# dm646x_cslr_edma3tc register map
Vendor: Texas Instruments
Peripheral module from a debugger description file.
Registers are 32-bit, access not given, reset 0x0 unless marked. A register's access mark holds for its fields unless they carry their own. Offsets are as the file gives them; lines under a group give offsets from that group; [hi:lo] are bit positions; {n}, {i} and the like mark numbered series; 'fields as' and 'values as' point back to an identical list; <NAME> marks a mode.

## EDMA3TC — Enhanced DMA Transfer controller.
0x00 PID ro — Peripheral Revision
{0x0+0x40*i} DFIREG[{i}] (i=0..3) group — Destination FIFO Registers
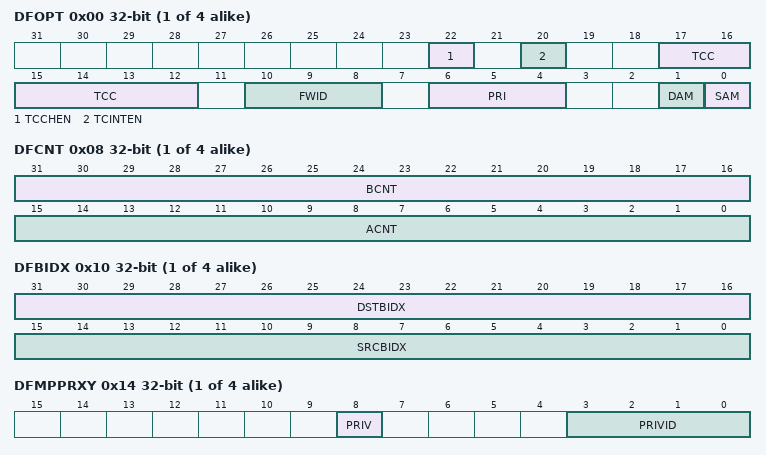
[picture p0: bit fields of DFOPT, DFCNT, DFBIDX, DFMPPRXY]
  0x00 DFOPT — Dst FIFO Set Option
    [22] TCCHEN rw — Transfer Complete chaining enable
      0=DISABLE (Transfer complete chaning disable); 1=ENABLE (Transfer complete chaning enable)
    [20] TCINTEN rw — Transfer Complete interrupt enable
      0=DISABLE (Transfer complete interrupt disable); 1=ENABLE (Transfer complete interrupt enable)
    [17:12] TCC rw — Transfer Complete Code
    [10:8] FWID rw — Fifo Width
      0=8BIT (Fifo Width is 8-bit); 1=16BIT (Fifo Width is 16-bit); 2=32BIT (Fifo Width is 32-bit); 3=64BIT (Fifo Width is 64-bit); 4=128BIT (Fifo Width is 128-bit); 5=256BIT (Fifo Width is 256-bit)
    [6:4] PRI rw — Transfer Priority
    [1] DAM rw — Destination address mode within array
      0=INCR (Dst addressing within array increments); 1=FIFO (Dst addressing within array wraps around upon reaching FIFO width)
    [0] SAM rw — Source address mode within array
      0=INCR (Src addressing within array increments); 1=FIFO (Src addressing within array wraps around upon reaching FIFO width)
  0x04 DFSRC ro — Dst Fifo Source address
    [31:0] SADDR — Will always read as '0'
  0x08 DFCNT ro — Dst Fifo Set Count
    [31:16] BCNT — B Dimension count
    [15:0] ACNT — A Dimension count
  0x0C DFDST ro — Destination FIFO Destination Address Register
    [31:0] DADDR — Dst Address
  0x10 DFBIDX ro — Dst Fifo Set B-Dim Idx
    [31:16] DSTBIDX — B-Idx offset between Destination arrays
    [15:0] SRCBIDX — Always read as 0
  0x14 DFMPPRXY — Dst Fifo mem Protect Proxy
    [8] PRIV ro — Privilege Level
      0=USER (User level privilege); 1=SUPERVISOR (Supervisor level privilege)
    [3:0] PRIVID ro — Privilege ID
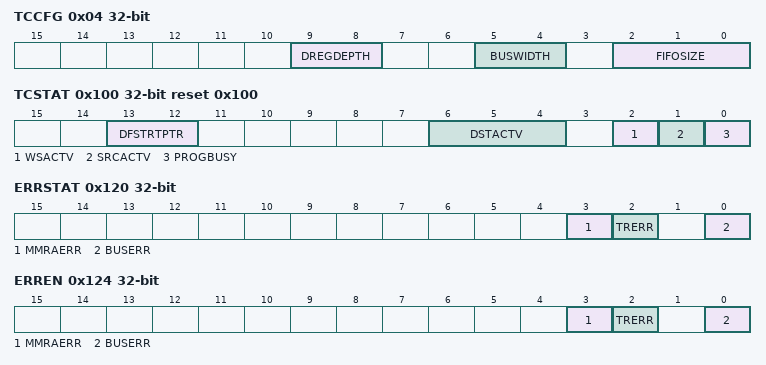
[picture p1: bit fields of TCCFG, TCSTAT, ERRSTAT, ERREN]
0x04 TCCFG — TC Configuration
  [9:8] DREGDEPTH ro — Destination Register FIFO Depth Parametization
    1=2ENTRY; 2=4ENTRY
  [5:4] BUSWIDTH ro — Bus width parameterization
    2=16BYTE
  [2:0] FIFOSIZE ro
    2=128BYTE (128 Byte Fifo); 3=256BYTE (256 Byte Fifo)
0x100 TCSTAT reset 0x100 — TPTC Status
  [13:12] DFSTRTPTR ro — Dst FIFO Start Pointer
  [6:4] DSTACTV ro — Destination Active State
    0=EMPTY (Dst FIFO is empty); {v}={v}TR (Dst FIFO contains {v} TR) (v=1..4)
  [2] WSACTV ro — Write Status Active
    0=NONE (Write status is not pending); 1=PEND (Write Status is pending)
  [1] SRCACTV ro — Source Active State
    0=IDLE (Source Active set is idle and available for programming); 1=BUSY
  [0] PROGBUSY ro — Program Register Set Busy
    0=IDLE (Idle and available for programming); 1=BUSY
0x120 ERRSTAT — Error Status
  [3] MMRAERR ro — MMR Address Error Event
    0=NONE (No error detected); 1=ERROR (User attempted to read/write invalid address)
  [2] TRERR ro — TR Error Event
    0=NONE (Condition not detected); 1=ERROR (FIFO Mode transfer violation)
  [0] BUSERR ro — Bus Error Event
    0=NONE (Condition not detected); 1=ERROR (TC has detected an error code on the read response)
0x124 ERREN — Error Enable
  [all] fields
    1=ENABLE; 0=DISABLE
  [3] MMRAERR rw — Interrupt enable for MMR address error
  [2] TRERR rw — Interrupt enable for transfer request error
  [0] BUSERR rw — Interrupt enable for bus error
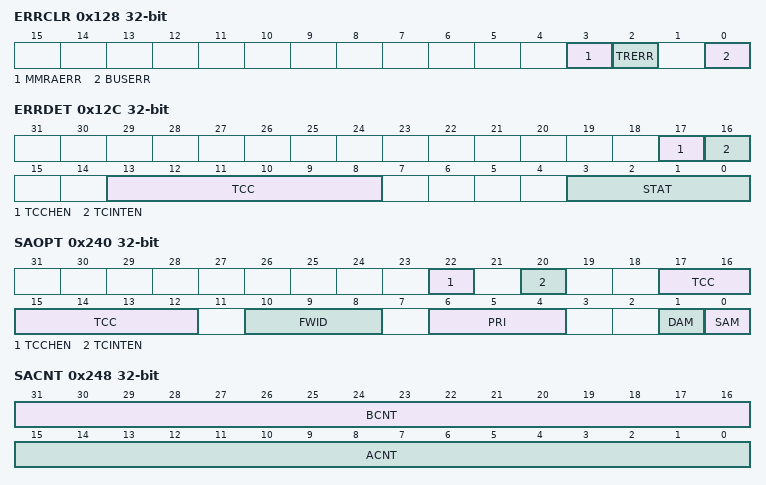
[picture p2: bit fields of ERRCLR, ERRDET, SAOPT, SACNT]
0x128 ERRCLR — Error Clear Register
  [all] fields
    1=CLEAR (Error Cleared)
  [3] MMRAERR wo — Interrupt enable clear for the MMRAERR bit in the error status register
  [2] TRERR wo — Interrupt enable clear for the TRERR bit in the error status register
  [0] BUSERR wo — Interrupt clear for the BUSERR bit in the error status register
0x12C ERRDET — Error Details
  [17] TCCHEN ro — Transfer Completion Chaining Enable
  [16] TCINTEN ro — Transfer Completion Interrupt Enable
  [13:8] TCC ro — Transfer Completion Code
  [3:0] STAT ro — Transaction Status
0x130 ERRCMD — Error Command
  [0] EVAL wo — Error evaluate
    1=EVAL (Write of '1' causes tptc_errint to be pulsed if any of the ERRSTAT bits are set to '1')
0x140 RDRATE — Read Command rate
  [2:0] RDRATE rw — Read rate
    0=AFAP (As Fast as possible); 1=4CYCLE (4 cycles between reads); 2=8CYCLE (8 cycles between reads); 3=16CYCLE (16 cycles between reads); 4=32CYCLE (32 cycles between reads)
0x240 SAOPT — Src Actv Set Options
  [22] TCCHEN rw — Transfer Complete chaining enable
    values as DFIREG[0].DFOPT.TCCHEN
  [20] TCINTEN rw — Transfer Complete interrupt enable
    values as DFIREG[0].DFOPT.TCINTEN
  [17:12] TCC rw — Transfer Complete Code
  [10:8] FWID rw — Fifo Width
    values as DFIREG[0].DFOPT.FWID
  [6:4] PRI rw — Transfer Priority
  [1] DAM rw — Destination address mode within an array
    values as DFIREG[0].DFOPT.DAM
  [0] SAM rw — Source address mode within an array
    values as DFIREG[0].DFOPT.SAM
0x244 SASRC ro — Src Actv Set Src Address
  [31:0] SADDR — Source address for Program Register Set
0x248 SACNT ro — Src Actv Set Count
  [31:16] BCNT — B Dimension count
  [15:0] ACNT — A Dimension count
0x24C SADST ro — Src Actv Dst address
  [31:0] DADDR — Always reads as '0'
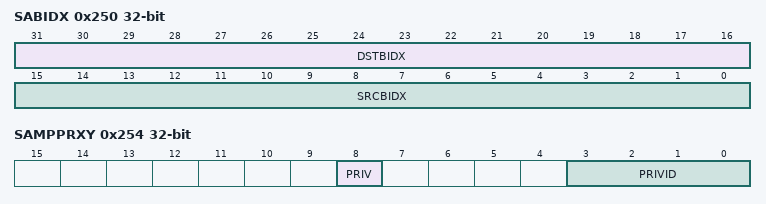
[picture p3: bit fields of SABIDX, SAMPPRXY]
0x250 SABIDX ro — Src Actv Set B-Dim Idx
  [31:16] DSTBIDX — B-Idx offset between Destination arrays
  [15:0] SRCBIDX — B-Idx offset between Source arrays
0x254 SAMPPRXY — Src Actv Set Mem Protect Proxy
  fields as DFIREG[0].DFMPPRXY
0x258 SACNTRLD — Src Actv Set Cnt Reload
  [15:0] ACNTRLD ro — A-cnt Reload value
0x25C SASRCBREF ro — Src Actv Set Src Address B-reference
  [31:0] SADDRBREF — Source address B-Reference
0x260 SADSTBREF ro — Src Actv Set Dst Address B-reference
  [31:0] DADDRBREF — Always reads s '0'
0x280 DFCNTRLD — Dst FIFO Set Cnt Reload
  [15:0] ACNTRLD ro — A-Cnt Reload value
0x284 DFSRCBREF ro — Dst FIFO Set Dst Addr B Reference
  [31:0] SADDRBREF — Always read as '0'
0x288 DFDSTBREF ro — Dst FIFO Set Dst Addr B Reference
  [31:0] DADDRBREF — Destination address reference for Dst FIFO Register Set
